# f2837xs_adc_result_regs register map
Vendor: Texas Instruments
Peripheral module from a debugger description file (folder C2000).
Address unit: 16 bits
Registers are 16-bit, read-only, no defined reset value unless marked. A register's access mark holds for its fields unless they carry their own. Offsets are as the file gives them; lines under a group give offsets from that group; [hi:lo] are bit positions; {n}, {i} and the like mark numbered series; 'fields as' and 'values as' point back to an identical list; <NAME> marks a mode.

## ADC_RESULT_REGS — ADC RESULT Registers
{0x0+i} ADCRESULT{i} (i=0..15)
  [15:0] RESULT — ADC Result
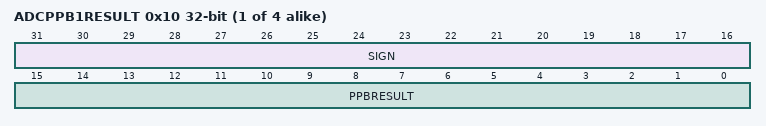
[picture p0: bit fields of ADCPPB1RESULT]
{0xE+2i} ADCPPB{i}RESULT 32-bit (i=1..4) — ADC Post Processing Block {i} Result Register
  [31:16] SIGN — Sign Extended Bits
  [15:0] PPBRESULT — ADC Post Processing Block Result
